# STM32U073xx register map
File version: 1.0
Registers are 32-bit, read-write, reset 0x0 unless marked. A register's access mark holds for its fields unless they carry their own. Offsets are from the block's base; [hi:lo] are bit positions; {n}, {i} and the like mark numbered series; 'fields as' and 'values as' point back to an identical list.

## DBGMCU — Debug MCU
Base 0x40015800
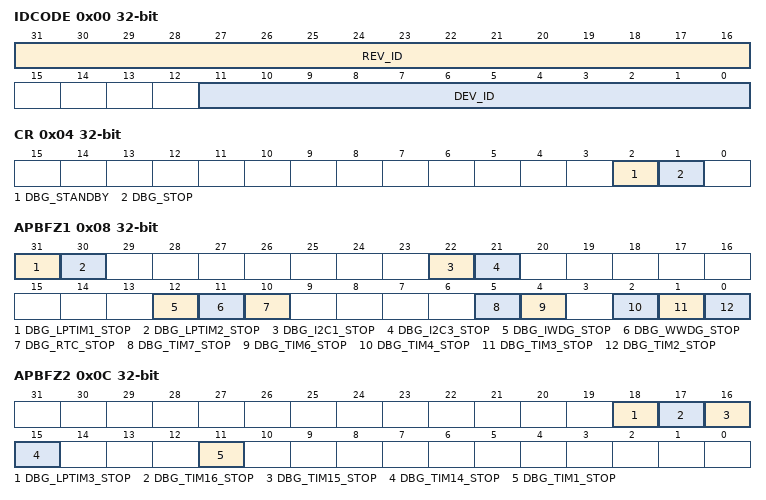
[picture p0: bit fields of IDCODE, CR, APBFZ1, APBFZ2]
0x00 IDCODE — MCU device ID code
  [31:16] REV_ID, [11:0] DEV_ID
0x04 CR — Debug configuration register
  [2] DBG_STANDBY, [1] DBG_STOP
0x08 APBFZ1 — Debug APB freeze register 1
  [31] DBG_LPTIM1_STOP, [30] DBG_LPTIM2_STOP, [22] DBG_I2C1_STOP, [21] DBG_I2C3_STOP, [12] DBG_IWDG_STOP, [11] DBG_WWDG_STOP, [10] DBG_RTC_STOP, [5] DBG_TIM7_STOP, [4] DBG_TIM6_STOP, [2] DBG_TIM4_STOP, [1] DBG_TIM3_STOP, [0] DBG_TIM2_STOP
0x0C APBFZ2 — Debug APB freeze register 2
  [18] DBG_LPTIM3_STOP, [17] DBG_TIM16_STOP, [16] DBG_TIM15_STOP, [15] DBG_TIM14_STOP, [11] DBG_TIM1_STOP

## DMA1
Base 0x40020000
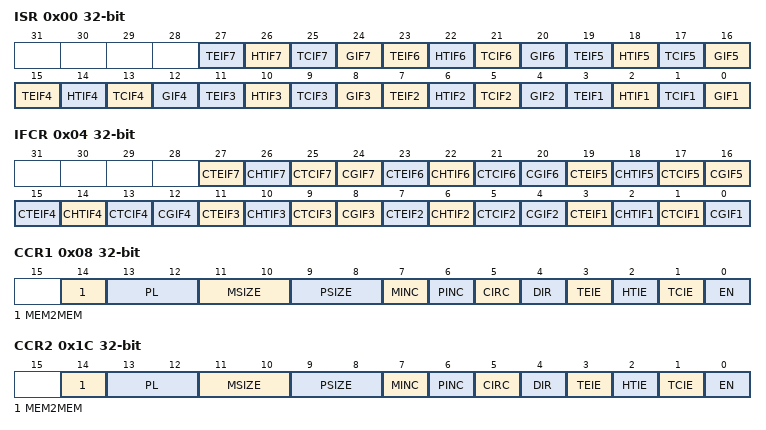
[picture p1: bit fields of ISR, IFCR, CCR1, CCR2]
0x00 ISR — DMA interrupt status register
  [4n-1] TEIF{n} (n=4..7) — Channel {n} Transfer Error flag
  [4n-2] HTIF{n} (n=1..7) — Channel {n} Half Transfer flag
  [4n-3] TCIF{n} (n=1..7) — Channel {n} Transfer Complete flag
  [4n-4] GIF{n} (n=1..7) — Channel {n} Global interrupt flag
  [11] TEIF3 — Channel 4 Transfer Error flag
  [7] TEIF2 — Channel 2 Transfer Error flag
  [3] TEIF1 — Channel 1 Transfer Error flag
0x04 IFCR — DMA interrupt flag clear register
  [4n-1] CTEIF{n} (n=1..7) — Channel {n} Transfer Error clear
  [4n-2] CHTIF{n} (n=1..7) — Channel {n} Half Transfer clear
  [4n-3] CTCIF{n} (n=1..7) — Channel {n} Transfer Complete clear
  [4n-4] CGIF{n} (n=2..7) — Channel {n} Global interrupt clear
  [0] CGIF1 — Channel 1 Global interrupt clearr
0x08 CCR1 — DMA channel x configuration register
  [14] MEM2MEM — Memory to memory mode
  [13:12] PL — PL[1:0] bits(Channel Priority level)
  [11:10] MSIZE — MSIZE[1:0] bits (Memory size)
  [9:8] PSIZE — PSIZE[1:0] bits (Peripheral size)
  [7] MINC — Memory increment mode
  [6] PINC — Peripheral increment mode
  [5] CIRC — Circular mode
  [4] DIR — Data transfer direction
  [3] TEIE — Transfer error interrupt enable
  [2] HTIE — Half Transfer interrupt enable
  [1] TCIE — Transfer complete interrupt enable
  [0] EN — Channel enable
0x0C CNDTR1 — DMA channel x number of data register
  [15:0] NDT — Number of data to Transfer
0x10 CPAR1 — DMA channel x peripheral address register
  [31:0] PA — Peripheral Address
{0x0+0x14*i} CMAR{i} (i=1..7) — DMA channel x memory address register
  [31:0] MA — Memory Address
0x1C CCR2 — DMA channel x configuration register
  fields as CCR1
0x20 CNDTR2 — DMA channel x number of data register
  [15:0] NDT — Number of data to Transfer
0x24 CPAR2 — DMA channel x peripheral address register
  [31:0] PA — Peripheral Address
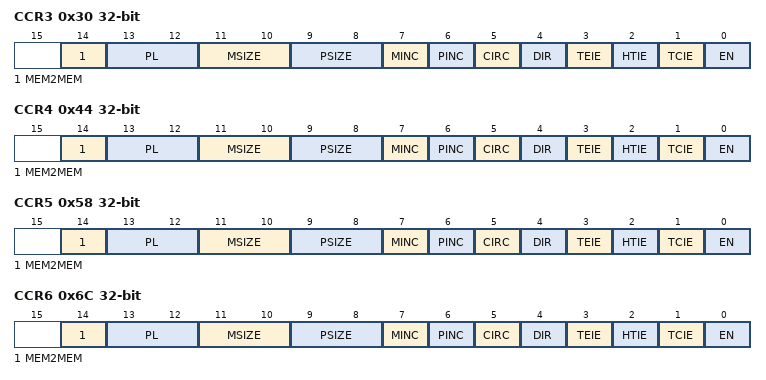
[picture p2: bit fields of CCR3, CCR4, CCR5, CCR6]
0x30 CCR3 — DMA channel x configuration register
  fields as CCR1
0x34 CNDTR3 — DMA channel x number of data register
  [15:0] NDT — Number of data to Transfer
0x38 CPAR3 — DMA channel x peripheral address register
  [31:0] PA — Peripheral Address
0x44 CCR4 — DMA channel x configuration register
  fields as CCR1
0x48 CNDTR4 — DMA channel x number of data register
  [15:0] NDT — Number of data to Transfer
0x4C CPAR4 — DMA channel x peripheral address register
  [31:0] PA — Peripheral Address
0x58 CCR5 — DMA channel x configuration register
  fields as CCR1
0x5C CNDTR5 — DMA channel x number of data register
  [15:0] NDT — Number of data to Transfer
0x60 CPAR5 — DMA channel x peripheral address register
  [31:0] PA — Peripheral Address
0x6C CCR6 — DMA channel x configuration register
  fields as CCR1
0x70 CNDTR6 — DMA channel x number of data register
  [15:0] NDT — Number of data to Transfer
0x74 CPAR6 — DMA channel x peripheral address register
  [31:0] PA — Peripheral Address
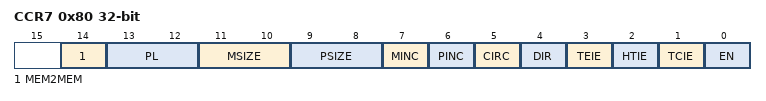
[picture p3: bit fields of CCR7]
0x80 CCR7 — DMA channel x configuration register
  fields as CCR1
0x84 CNDTR7 — DMA channel x number of data register
  [15:0] NDT — Number of data to Transfer
0x88 CPAR7 — DMA channel x peripheral address register
  [31:0] PA — Peripheral Address

## DMA2
Base 0x40020400
Registers as DMA1, without CCR6, CNDTR6, CPAR6, CMAR6, CCR7, CNDTR7, CPAR7, CMAR7.
